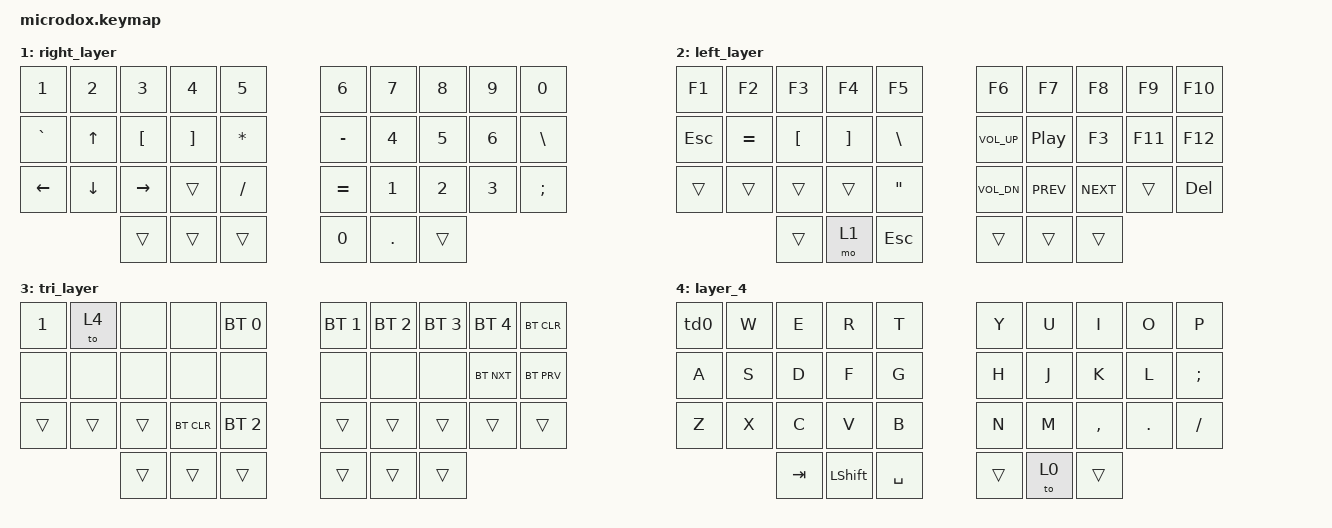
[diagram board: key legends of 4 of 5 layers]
// Copyright (c) 2022 The ZMK Contributors
// SPDX-License-Identifier: MIT

#include <behaviors.dtsi>
#include <dt-bindings/zmk/keys.h>
#include <dt-bindings/zmk/bt.h>

// Home row mods macro
#define HRML(k1,k2,k3,k4) &ht LSHFT k1  &ht LALT k2  &ht LCTRL k3  &ht LGUI k4
#define HRMR(k1,k2,k3,k4) &ht RGUI k1  &ht RCTRL k2  &ht RALT k3  &ht RSHFT k4

/ {
    behaviors {
        ht: hold_tap {
            compatible = "zmk,behavior-hold-tap";
            #binding-cells = <2>;
            flavor = "tap-preferred";
            tapping-term-ms = <220>;
            quick-tap-ms = <150>;
            require-prior-idle-ms = <100>;
            bindings = <&kp>, <&kp>;
        };
          td0: tap_dance_0 {
            compatible = "zmk,behavior-tap-dance";
            #binding-cells = <0>;
            tapping-term-ms = <200>;
            bindings = <&kp Q>, <&kp ESC>;
    };

    conditional_layers {
        compatible = "zmk,conditional-layers";
        tri_layer {
            if-layers = <1 2>;
            then-layer = <3>;
        };
    };
};
    keymap {
        compatible = "zmk,keymap";
        default_layer {
            bindings = <
        //╭──────────┬──────────┬──────────┬──────────┬──────────╮   ╭──────────┬──────────┬──────────┬──────────┬──────────╮
        //│  Q       │  W       │  E       │  R       │  T       │   │  Y       │  U       │  I       │  O       │  P       │
            &td0     &kp W      &kp E      &kp R      &kp T          &kp Y      &kp U      &kp I      &kp O      &kp P
        //├──────────┼──────────┼──────────┼──────────┼──────────┤   ├──────────┼──────────┼──────────┼──────────┼──────────┤
        //│  A       │  S       │  D       │  F       │  G       │   │  H       │  J       │  K       │  L       │ ' "      │
            HRML(A,        S,         D,         F)     &kp G          &kp H      HRMR(J,        K,         L,        SQT)
        //├──────────┼──────────┼──────────┼──────────┼──────────┤   ├──────────┼──────────┼──────────┼──────────┼──────────┤
        //│  Z       │  X       │  C       │  V       │  B       │   │  N       │  M       │ , <      │ . >      │ / ?      │
           &mt LCTRL Z  &kp X      &kp C      &kp V      &kp B          &kp N      &kp M      &kp COMMA  &kp DOT    &kp FSLH
        //╰──────────┴──────────┴──────────┼──────────┼──────────┤   ├──────────┼──────────┼──────────┴──────────┴──────────╯
                                    &kp LALT &lt 1 TAB   &kp SPACE     &mt RSHFT RET  &lt 2 BSPC &kp DEL
        //                                 ╰──────────┴──────────╯   ╰──────────┴──────────╯
            >;
        };

        right_layer {
            bindings = <
       //╭──────────┬──────────┬──────────┬──────────┬──────────╮   ╭──────────┬──────────┬──────────┬──────────┬──────────╮
        //│     1   │    2     │     3    │  4      │     5     │   │      6    │        7 │        8 │        9 │  :0      │
            &kp N1     &kp N2     &kp N3    &kp N4       &kp N5         &kp N6      &kp N7     &kp N8      &kp N9   &kp N0
        //├──────────┼──────────┼──────────┼──────────┼──────────┤   ├──────────┼──────────┼──────────┼──────────┼──────────┤
        //│   Grave │up│  Left Bracket │  Right Bracket │          │   │Minus     │ 4   │ 5   │ 6    │  \       │
            &kp GRAVE    &kp UP &kp LEFT_BRACKET &kp RIGHT_BRACKET  &kp ASTERISK &kp MINUS &kp N4 &kp N5 &kp N6 &kp BACKSLASH
        //├──────────┼──────────┼──────────┼──────────┼──────────┤   ├──────────┼──────────┼──────────┼──────────┼──────────┤
        //│ left     │  down      │  right       │  9       │  0       │   │          │          │          │          │          │
            &kp LEFT   &kp DOWN    &kp RIGHT &trans &kp SLASH        &kp EQUAL  &kp N1    &kp N2    &kp N3 &kp SEMI
        //╰──────────┴──────────┴──────────┼──────────┼──────────┤   ├──────────┼──────────┼──────────┴──────────┴──────────╯
                                          &trans     &trans     &trans       &kp N0    &kp DOT &trans 
        //                                 ╰──────────┴──────────╯   ╰──────────┴──────────╯
            >;
        };

        left_layer {
            bindings = <
         //╭──────────┬──────────┬──────────┬──────────┬──────────╮   ╭──────────┬──────────┬──────────┬──────────┬──────────╮
        //│   F1      │  F2      │  F3      │ F4      │    F5      │   │  F6      │ F7      │ F8    │  F9     │  F10       │
            &kp F1    &kp F2    &kp F3    &kp F4    &kp F5        &kp F6   &kp F7    &kp F8    &kp F9    &kp F10
        //├──────────┼──────────┼──────────┼──────────┼──────────┤   ├──────────┼──────────┼──────────┼──────────┼──────────┤
        //│  esc       │  @       │  #       │  $       │  %       │   │  *       │  -       │  =       │  \       │  `       │
            &kp ESC &kp EQUAL &kp LEFT_BRACKET  &kp RIGHT_BRACKET  &kp BSLH      &kp C_VOL_UP    &kp C_PLAY_PAUSE    &kp F3    &kp F11   &kp F12
        //├──────────┼──────────┼──────────┼──────────┼──────────┤   ├──────────┼──────────┼──────────┼──────────┼──────────┤
        //│          │          │          │          │          │   │  &       │  _       │  +       │  │       │          │
            &trans  &trans &trans &trans &kp DQT       &kp C_VOL_DN    &kp C_PREV    &kp C_NEXT    &trans   &kp DEL
        //╰──────────┴──────────┴──────────┼──────────┼──────────┤   ├──────────┼──────────┼──────────┴──────────┴──────────╯
                                     &trans     &mo 1    &kp ESC        &trans     &trans &trans 
        //                                 ╰──────────┴──────────╯   ╰──────────┴──────────╯
            >;
        };

        tri_layer {
            bindings = <
        //╭──────────┬──────────┬──────────┬──────────┬──────────╮   ╭──────────┬──────────┬──────────┬──────────┬──────────╮
        //│ ESC    │          │          │          │PROFILE 0 │   │          │          │          │          │  RESET   │
           &kp N1       &to 4   &none        &none   &bt BT_SEL 0 &bt BT_SEL 1 &bt BT_SEL 2 &bt BT_SEL 3 &bt BT_SEL 4 &bt BT_CLR
        //├──────────┼──────────┼──────────┼──────────┼──────────┤   ├──────────┼──────────┼──────────┼──────────┼──────────┤
        //│BOOTLOADER│          │          │          │PROFILE 1 │   │          │          │          │          │BOOTLOADER│
          &none        &none        &none        &none              &none        &none        &none        &none        &bt BT_NXT        &bt BT_PRV
        //├──────────┼──────────┼──────────┼──────────┼──────────┤   ├──────────┼──────────┼──────────┼──────────┼──────────┤
        //│          │          │          │ CLEAR BT │PROFILE 2 │   │          │          │          │          │          │
            &trans     &trans     &trans    &bt BT_CLR &bt BT_SEL 2    &trans     &trans     &trans     &trans     &trans
        //╰──────────┴──────────┴──────────┼──────────┼──────────┤   ├──────────┼──────────┼──────────┴──────────┴──────────╯
                                           &trans    &trans     &trans         &trans     &trans &trans 
        //                                 ╰──────────┴──────────╯   ╰──────────┴──────────╯
            >;
        };
    layer_4 {
            bindings = <
&td0  &kp W  &kp E   &kp R           &kp T        &kp Y   &kp U  &kp I      &kp O    &kp P 
&kp A  &kp S  &kp D   &kp F           &kp G        &kp H   &kp J  &kp K      &kp L    &kp SEMI
&kp Z  &kp X  &kp C   &kp V           &kp B        &kp N   &kp M  &kp COMMA  &kp DOT  &kp FSLH
                      &kp TAB  &kp LEFT_SHIFT  &kp SPACE    &trans  &to 0  &trans
            >;
        };


};
};
